# Template register map
Vendor: VendorName Co.Ltd; Series: SeriesName; File version: 1.2
CPU: CM7 r0p1, little endian, MPU, FPU, 4 interrupt priority bits
Registers are 32-bit, read-write, no defined reset value unless marked. A register's access mark holds for its fields unless they carry their own. Offsets are from the block's base; [hi:lo] are bit positions; 'fields as' and 'values as' point back to an identical list.

## UPP — Universal Parallel Port
Base 0x4009A000
0x00 PID ro — UPP peripheral ID register
  [31:0] REVID — UPP REVID[31:0] bit: module revise ID
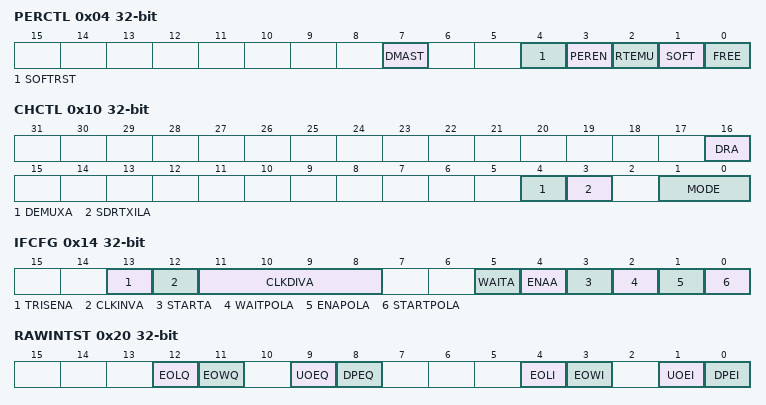
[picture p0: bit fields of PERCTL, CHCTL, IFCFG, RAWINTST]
0x04 PERCTL — UPP peripheral control register
  [7] DMAST ro — UPP DMAST bit: DMA state machine state
  [4] SOFTRST — UPP SOFTRST bit: reset all state machines and certain memory elements within the module
  [3] PEREN — UPP PEREN bit: prohibit or suspend the RPI module
  [2] RTEMU — UPP RTEMU bit: real-time emulation enable
  [1] SOFT — UPP SOFT bit: soft stop
  [0] FREE — UPP FREE bit: free operation
0x10 CHCTL — UPP general control register
  [16] DRA — UPP DRA bit: data speed control
  [4] DEMUXA — UPP DEMUXA bit: DDR demux mode
  [3] SDRTXILA — UPP SDRTXILA bit: Tx SDR stagger mode
  [1:0] MODE — UPP MODE[1:0] bit: mode select
0x14 IFCFG — UPP interface configuration register
  [13] TRISENA — UPP TRISENA bit: send mode output tristate control
  [12] CLKINVA — UPP CLKINVA bit: clock inverse
  [11:8] CLKDIVA — UPP CLKDIVA[3:0] bit: clock frequency division value of sending mode
  [5] WAITA — UPP WAITA bit: start WAIT signal
  [4] ENAA — UPP ENAA bit: start ENABLE signal
  [3] STARTA — UPP STARTA bit: start START signal
  [2] WAITPOLA — UPP WAITPOLA bit: WAIT signal polarity
  [1] ENAPOLA — UPP ENAPOLA bit: ENABLE signal polarity
  [0] STARTPOLA — UPP STARTPOLA bit: START signal polarity
0x18 IFIVAL — UPP interface empty value register
  [8:0] VALA — UPP VALA[8:0] bit: save the value to be output when the channel is idle
0x20 RAWINTST — UPP raw interrupt status register
  [12] EOLQ — UPP EOLQ bit: the original state of the interrupt for end condition of row
  [11] EOWQ — UPP EOWQ bit: the original state of the interrupt for end condition of window
  [9] UOEQ — UPP UOEQ bit: the original state of the interrupt of DMA underload or overload
  [8] DPEQ — UPP DPEQ bit: the original state of the interrupt of DMA programming error
  [4] EOLI — UPP EOLI bit: original interrupt enable for end condition of row
  [3] EOWI — UPP EOWI bit: original interrupt enable for end condition of window
  [1] UOEI — UPP UOEI bit: original interrupt enable of DMA underload or overload
  [0] DPEI — UPP DPEI bit: original interrupt enable of DMA programming error
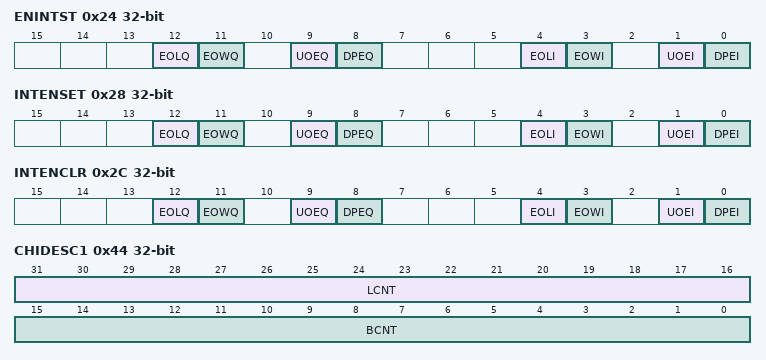
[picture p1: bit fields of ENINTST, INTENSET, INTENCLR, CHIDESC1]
0x24 ENINTST — UPP enable interrupt status register
  [12] EOLQ — UPP EOLQ bit: the state of the interrupt for end condition of row
  [11] EOWQ — UPP EOWQ bit: the state of the interrupt for end condition of window
  [9] UOEQ — UPP UOEQ bit: the state of the interrupt of DMA underload or overload
  [8] DPEQ — UPP DPEQ bit: the state of the interrupt of DMA programming error
  [4] EOLI — UPP EOLI bit: interrupt enable for end condition of row
  [3] EOWI — UPP EOWI bit: interrupt enable for end condition of window
  [1] UOEI — UPP UOEI bit: interrupt enable of DMA underload or overload
  [0] DPEI — UPP DPEI bit: interrupt enable of DMA programming error
0x28 INTENSET wo — UPP interrupt enable set register
  [12] EOLQ — UPP EOLQ bit: set interrupt enable for end condition of row
  [11] EOWQ — UPP EOWQ bit: set interrupt enable for end condition of window
  [9] UOEQ — UPP UOEQ bit: set interrupt enable of DMA underload or overload
  [8] DPEQ — UPP DPEQ bit: set interrupt enable of DMA programming error
  [4] EOLI — UPP EOLI bit: end condition of row interrupt enable set
  [3] EOWI — UPP EOWI bit: end condition of window interrupt enable set
  [1] UOEI — UPP UOEI bit: DMA underload or overload interrupt enable set
  [0] DPEI — UPP DPEI bit: DMA programming error interrupt enable set
0x2C INTENCLR wo — UPP interrupt enable clear register
  [12] EOLQ — UPP EOLQ bit: interrupt clear for end condition of row
  [11] EOWQ — UPP EOWQ bit: interrupt clear for end condition of window
  [9] UOEQ — UPP UOEQ bit: interrupt clear of DMA underload or overload
  [8] DPEQ — UPP DPEQ bit: interrupt clear of DMA programming error
  [4] EOLI — UPP EOLI bit: end condition of row interrupt clear bit
  [3] EOWI — UPP EOWI bit: end condition of window interrupt clear bit
  [1] UOEI — UPP UOEI bit: DMA underload or overload interrupt clear bit
  [0] DPEI — UPP DPEI bit: DMA programming error interrupt clear bit
0x40 CHIDESC0 — UPP DMA channel I descriptor 0 register
  [31:0] ADDR — UPP ADDR[31:0] bit: initial address of DMA channel I transmission
0x44 CHIDESC1 — UPP DMA channel I descriptor 1 register
  [31:16] LCNT — UPP LCNT[15:0] bit: row number of DMA channel I transmission window
  [15:0] BCNT — UPP BCNT[15:0] bit: row byte number of DMA channel I transmission window
0x48 CHIDESC2 — UPP DMA channel I descriptor 2 register
  [15:0] LOFFSET — UPP LOFFSET[15:0] bit: offset from current row address to next row address of DMA channel I transmission
0x50 CHIST0 ro — UPP DMA channel I status 0 register
  [31:0] ADDR — UPP ADDR[31:0] bit: DMA transmit current address
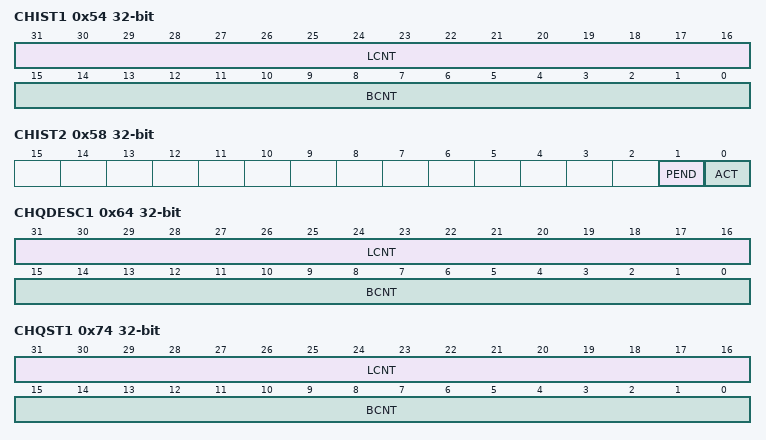
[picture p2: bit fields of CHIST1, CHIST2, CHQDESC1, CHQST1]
0x54 CHIST1 ro — UPP DMA channel I status 1 register
  [31:16] LCNT — UPP LCNT[15:0] bit: current row number
  [15:0] BCNT — UPP BCNT[15:0] bit: current byte number
0x58 CHIST2 ro — UPP DMA channel I status 2 register
  [1] PEND — UPP PEND bit: DMA state
  [0] ACT — UPP ACT bit: DMA descriptor state
0x60 CHQDESC0 — UPP DMA channel Q descriptor 0 register
  [31:0] ADDR — UPP ADDR[31:0] bit: initial address of DMA channel Q transmission
0x64 CHQDESC1 — UPP DMA channel Q descriptor 1 register
  [31:16] LCNT — UPP LCNT[15:0] bit: row number of DMA channel Q transmission window
  [15:0] BCNT — UPP BCNT[15:0] bit: row byte number of DMA channel Q transmission window
0x68 CHQDESC2 — UPP DMA channel Q descriptor 2 register
  [15:0] LOFFSET — UPP LOFFSET[15:0] bit: offset from current row address to next row address of DMA channel Q transmission
0x70 CHQST0 ro — UPP DMA channel Q status 0 register
  [31:0] ADDR — UPP ADDR[31:0] bit: DMA transmit current address
0x74 CHQST1 ro — UPP DMA channel Q status 1 register
  fields as CHIST1
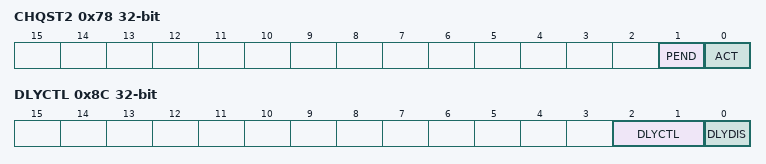
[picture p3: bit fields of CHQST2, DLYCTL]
0x78 CHQST2 ro — UPP DMA channel Q status 2 register
  fields as CHIST2
0x80 GINTEN — UPP global peripheral interrupt enable register
  [0] GINTEN — UPP GINTEN bit: global interrupt enable
0x84 GINTFLG ro — UPP global peripheral interrupt flag register
  [0] GINTFLG — UPP GINTFLG bit: global interrupt flag
0x88 GINTCLR wo — UPP global peripheral interrupt clear register
  [0] GINTCLR — UPP GINTCLR bit: global interrupt clear
0x8C DLYCTL — UPP IO clock data skew control register
  [2:1] DLYCTL — UPP DLYCTL[1:0] bit: control UPP input signal delay
  [0] DLYDIS — UPP DLYDIS bit: START signal polarity
